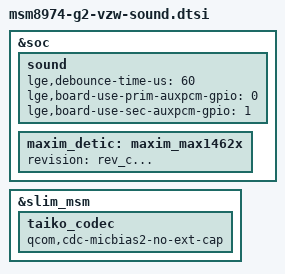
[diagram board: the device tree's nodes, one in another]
/* Copyright (c) 2013, LGE Electronics. All rights reserved.
 *
 * This program is free software; you can redistribute it and/or modify
 * it under the terms of the GNU General Public License version 2 and
 * only version 2 as published by the Free Software Foundation.
 *
 * This program is distributed in the hope that it will be useful,
 * but WITHOUT ANY WARRANTY; without even the implied warranty of
 * MERCHANTABILITY or FITNESS FOR A PARTICULAR PURPOSE.  See the
 * GNU General Public License for more details.
 */

&soc {

	sound {
		lge,debounce-time-us = <60>;
		lge,board-use-prim-auxpcm-gpio = <0>;
		lge,board-use-sec-auxpcm-gpio = <1>;
	};

	maxim_detic:maxim_max1462x {
		status = "ok";
		revision = "rev_c...";
	};

};

&slim_msm {
	taiko_codec {
		qcom,cdc-micbias2-no-ext-cap;
	};
};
